# R7FA2A1AB register map
Vendor: Renesas; Series: RA2; File version: 1.1
CPU: CM23 r1p0, little endian, MPU, no FPU, VTOR, 2 interrupt priority bits
Registers are 8-bit, read-write, reset 0x0 unless marked. A register's access mark holds for its fields unless they carry their own. Offsets are from the block's base; [hi:lo] are bit positions; {n}, {i} and the like mark numbered series.

## IIC0 — Inter,Integrated Circuit 0
Base 0x40053000
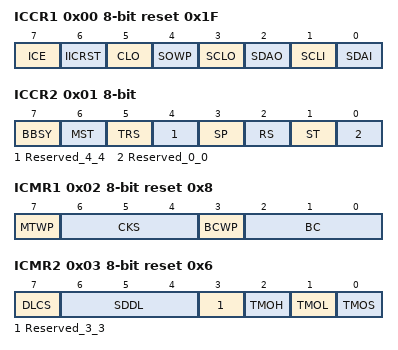
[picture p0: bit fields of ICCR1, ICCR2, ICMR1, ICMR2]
0x00 ICCR1 reset 0x1F — I2C Bus Control Register 1
  [7] ICE — I2C Bus Interface Enable
  [6] IICRST — I2C Bus Interface Internal ResetNote:If an internal reset is initiated using the IICRST bit for a bus hang,up occurred during communication with the master device in slave mode, the states may become different between the slave device and the master device (due to the difference in the bit counter information).
  [5] CLO — Extra SCL Clock Cycle Output
  [4] SOWP wo — SCLO/SDAO Write Protect
  [3] SCLO — SCL Output Control/Monitor
  [2] SDAO — SDA Output Control/Monitor
  [1] SCLI ro — SCL Line Monitor
  [0] SDAI ro — SDA Line Monitor
0x01 ICCR2 — I2C Bus Control Register 2
  [7] BBSY ro — Bus Busy Detection Flag
  [6] MST — Master/Slave Mode
  [5] TRS — Transmit/Receive Mode
  [4] Reserved_4_4 — This bit is read as 0. The write value should be 0.
  [3] SP — Stop Condition Issuance RequestNote: Writing to the SP bit is not possible while the setting of the BBSY flag is 0 (bus free state).Note: Do not set the SP bit to 1 while a restart condition is being issued.
  [2] RS — Restart Condition Issuance RequestNote: Do not set the RS bit to 1 while issuing a stop condition.
  [1] ST — Start Condition Issuance RequestSet the ST bit to 1 (start condition issuance request) when the BBSY flag is set to 0 (bus free state).
  [0] Reserved_0_0 — This bit is read as 0. The write value should be 0.
0x02 ICMR1 reset 0x8 — I2C Bus Mode Register 1
  [7] MTWP — MST/TRS Write Protect
  [6:4] CKS — Internal Reference Clock (fIIC) Selection ( fIIC = PCLKB / 2^CKS )
  [3] BCWP wo — BC Write Protect(This bit is read as 1.)
  [2:0] BC — Bit Counter
0x03 ICMR2 reset 0x6 — I2C Bus Mode Register 2
  [7] DLCS — SDA Output Delay Clock Source Selection
  [6:4] SDDL — SDA Output Delay Counter
  [3] Reserved_3_3 — This bit is read as 0. The write value should be 0.
  [2] TMOH — Timeout H Count Control
  [1] TMOL — Timeout L Count Control
  [0] TMOS — Timeout Detection Time Selection
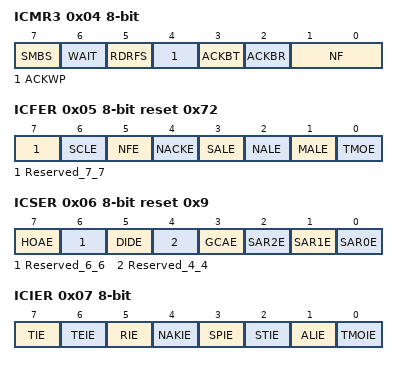
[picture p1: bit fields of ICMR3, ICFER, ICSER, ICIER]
0x04 ICMR3 — I2C Bus Mode Register 3
  [7] SMBS — SMBus/I2C Bus Selection
  [6] WAIT — WAITNote: When the value of the WAIT bit is to be read, be sure to read the ICDRR beforehand.
  [5] RDRFS — RDRF Flag Set Timing Selection
  [4] ACKWP — ACKBT Write Protect
  [3] ACKBT — Transmit Acknowledge
  [2] ACKBR ro — Receive Acknowledge
  [1:0] NF — Noise Filter Stage Selection
0x05 ICFER reset 0x72 — I2C Bus Function Enable Register
  [7] Reserved_7_7 — This bit is read as 0. The write value should be 0.
  [6] SCLE — SCL Synchronous Circuit Enable
  [5] NFE — Digital Noise Filter Circuit Enable
  [4] NACKE — NACK Reception Transfer Suspension Enable
  [3] SALE — Slave Arbitration,Lost Detection Enable
  [2] NALE — NACK Transmission Arbitration,Lost Detection Enable
  [1] MALE — Master Arbitration,Lost Detection Enable
  [0] TMOE — Timeout Function Enable
0x06 ICSER reset 0x9 — I2C Bus Status Enable Register
  [7] HOAE — Host Address Enable
  [6] Reserved_6_6 — This bit is read as 0. The write value should be 0.
  [5] DIDE — Device,ID Address Detection Enable
  [4] Reserved_4_4 — This bit is read as 0. The write value should be 0.
  [3] GCAE — General Call Address Enable
  [2] SAR2E — Slave Address Register 2 Enable
  [1] SAR1E — Slave Address Register 1 Enable
  [0] SAR0E — Slave Address Register 0 Enable
0x07 ICIER — I2C Bus Interrupt Enable Register
  [7] TIE — Transmit Data Empty Interrupt Request Enable
  [6] TEIE — Transmit End Interrupt Request Enable
  [5] RIE — Receive Data Full Interrupt Request Enable
  [4] NAKIE — NACK Reception Interrupt Request Enable
  [3] SPIE — Stop Condition Detection Interrupt Request Enable
  [2] STIE — Start Condition Detection Interrupt Request Enable
  [1] ALIE — Arbitration,Lost Interrupt Request Enable
  [0] TMOIE — Timeout Interrupt Request Enable
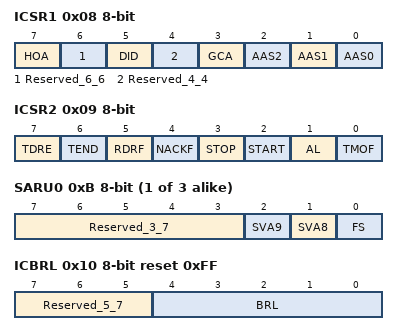
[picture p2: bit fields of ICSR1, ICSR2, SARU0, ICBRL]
0x08 ICSR1 — I2C Bus Status Register 1
  [7] HOA write-0-clears read-modifies — Host Address Detection Flag
  [6] Reserved_6_6 — This bit is read as 0. The write value should be 0.
  [5] DID write-0-clears read-modifies — Device,ID Address Detection Flag
  [4] Reserved_4_4 — This bit is read as 0. The write value should be 0.
  [3] GCA write-0-clears read-modifies — General Call Address Detection Flag
  [2] AAS2 write-0-clears read-modifies — Slave Address 2 Detection Flag
  [1] AAS1 write-0-clears read-modifies — Slave Address 1 Detection Flag
  [0] AAS0 write-0-clears read-modifies — Slave Address 0 Detection Flag
0x09 ICSR2 — I2C Bus Status Register 2
  [7] TDRE ro — Transmit Data Empty Flag
  [6] TEND write-0-clears read-modifies — Transmit End Flag
  [5] RDRF write-0-clears read-modifies — Receive Data Full Flag
  [4] NACKF write-0-clears read-modifies — NACK Detection Flag
  [3] STOP write-0-clears read-modifies — Stop Condition Detection Flag
  [2] START write-0-clears read-modifies — Start Condition Detection Flag
  [1] AL write-0-clears read-modifies — Arbitration,Lost Flag
  [0] TMOF write-0-clears read-modifies — Timeout Detection Flag
{0xA+2i} SARL{i} (i=0..2) — Slave Address Register L{i}
  [7:0] SVA — A slave address is set.7-Bit Address = SVA[7:1] 10-Bit Address = { SVA9,SVA8,SVA[7:0] }
{0xB+2i} SARU{i} (i=0..2) — Slave Address Register U{i}
  [7:3] Reserved_3_7 — These bits are read as 00000. The write value should be 00000.
  [2] SVA9 — 10-Bit Address(bit9)
  [1] SVA8 — 10-Bit Address(bit8)
  [0] FS — 7-Bit/10-Bit Address Format Selection
0x10 ICBRL reset 0xFF — I2C Bus Bit Rate Low,Level Register
  [7:5] Reserved_5_7 — These bits are read as 111. The write value should be 111.
  [4:0] BRL — Bit Rate Low,Level Period(Low,level period of SCL clock)
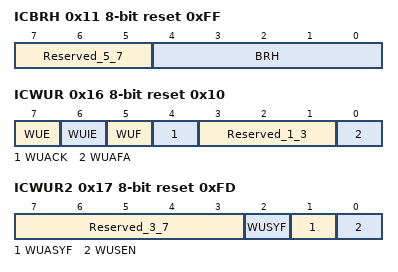
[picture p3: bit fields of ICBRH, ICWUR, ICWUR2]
0x11 ICBRH reset 0xFF — I2C Bus Bit Rate High,Level Register
  [7:5] Reserved_5_7 — These bits are read as 111. The write value should be 111.
  [4:0] BRH — Bit Rate High,Level Period(High,level period of SCL clock)
0x12 ICDRT reset 0xFF — I2C Bus Transmit Data Register
  [7:0] ICDRT — 8-bit read,write register that stores transmit data.
0x13 ICDRR ro — I2C Bus Receive Data Register
  [7:0] ICDRR — 8-bit register that stores the received data
0x16 ICWUR reset 0x10 — I2C Bus Wake Up Unit Register
  [7] WUE — Wake Up function Enable
  [6] WUIE — Wake Up Interrupt Request Enable
  [5] WUF — Wake,Up Event Occurrence Flag
  [4] WUACK — Asynchronous/Synchronous Operation State Flag
  [3:1] Reserved_1_3 — These bits are read as 000. The write value should be 000.
  [0] WUAFA — Wake,Up Analog Filter Additional Selection
0x17 ICWUR2 reset 0xFD — Reserved
  [7:3] Reserved_3_7 — These bits are read as 11111. The write value should be 11111.
  [2] WUSYF ro — Wake,Up function Synchronous operation status Flag
  [1] WUASYF ro — Wake,Up function Asynchronous operation status Flag
  [0] WUSEN — Wake,Up function Synchronous Enable

## IIC1 — Inter,Integrated Circuit 1
Base 0x40053100
Registers as IIC0, without ICWUR, ICWUR2; these are added or differ:
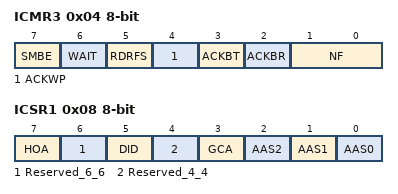
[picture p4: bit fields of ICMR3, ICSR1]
0x04 ICMR3 — I2C Bus Mode Register 3
  [7] SMBE — SMBus/I2C Bus Selection
  [6] WAIT — WAITNote: When the value of the WAIT bit is to be read, be sure to read the ICDRR beforehand.
  [5] RDRFS — RDRF Flag Set Timing Selection
  [4] ACKWP — ACKBT Write Protect
  [3] ACKBT — Transmit Acknowledge
  [2] ACKBR ro — Receive Acknowledge
  [1:0] NF — Noise Filter Stage Selection
0x08 ICSR1 — I2C Bus Status Register 1
  [7] HOA write-0-clears read-modifies — Host Address Detection Flag
  [6] Reserved_6_6 — This bit is read as 0. The write value should be 0.
  [5] DID — Device,ID Address Detection Flag
  [4] Reserved_4_4 — This bit is read as 0. The write value should be 0.
  [3] GCA — General Call Address Detection Flag
  [2] AAS2 write-0-clears read-modifies — Slave Address 2 Detection Flag
  [1] AAS1 write-0-clears read-modifies — Slave Address 1 Detection Flag
  [0] AAS0 write-0-clears read-modifies — Slave Address 0 Detection Flag
